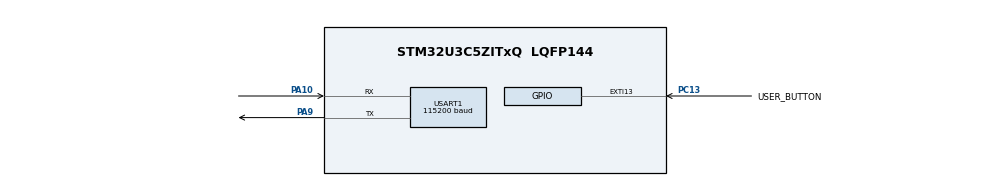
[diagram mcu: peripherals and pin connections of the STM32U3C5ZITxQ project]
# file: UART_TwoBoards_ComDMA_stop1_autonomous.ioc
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CORTEX_M33_NS.userName=CORTEX_M33
GPDMA1.DESTINC_GPDMACH0=DMA_DINC_INCREMENTED
GPDMA1.DESTINC_GPDMACH1=DMA_DINC_FIXED
GPDMA1.DIRECTION_GPDMACH0=DMA_PERIPH_TO_MEMORY
GPDMA1.DIRECTION_GPDMACH1=DMA_MEMORY_TO_PERIPH
GPDMA1.IPHANDLE_GPDMACH0-SIMPLEREQUEST_GPDMACH0=__NULL
GPDMA1.IPHANDLE_GPDMACH1-SIMPLEREQUEST_GPDMACH1=__NULL
GPDMA1.REQUEST_GPDMACH0=GPDMA1_REQUEST_USART1_RX
GPDMA1.REQUEST_GPDMACH1=GPDMA1_REQUEST_USART1_TX
GPDMA1.SRCINC_GPDMACH0=DMA_SINC_FIXED
GPDMA1.SRCINC_GPDMACH1=DMA_SINC_INCREMENTED
GPDMA1.TRANSFERALLOCATEDPORTDEST_GPDMACH0=DMA_DEST_ALLOCATED_PORT1
GPDMA1.TRANSFERALLOCATEDPORTDEST_GPDMACH1=DMA_DEST_ALLOCATED_PORT1
GPDMA1.TRANSFERALLOCATEDPORTSRC_GPDMACH0=DMA_SRC_ALLOCATED_PORT0
GPDMA1.TRANSFERALLOCATEDPORTSRC_GPDMACH1=DMA_SRC_ALLOCATED_PORT0
Mcu.Family=STM32U3
Mcu.Name=STM32U3C5ZITxQ
Mcu.Package=LQFP144
NVIC.EXTI13_IRQn=true\:0\:0\:false\:false\:true\:true\:true\:true
NVIC.GPDMA1_Channel0_IRQn=true\:0\:0\:false\:false\:true\:false\:true\:true
NVIC.GPDMA1_Channel1_IRQn=true\:0\:0\:false\:false\:true\:false\:true\:true
NVIC.PriorityGroup=NVIC_PRIORITYGROUP_4
NVIC.USART1_IRQn=true\:0\:0\:false\:false\:true\:true\:true\:true
PA10.GPIO_PuPd=GPIO_PULLUP
PA10.Mode=Asynchronous
PA10.Signal=USART1_RX
PA9.GPIO_PuPd=GPIO_PULLUP
PA9.Mode=Asynchronous
PA9.Signal=USART1_TX
PC13.GPIO_Label=USER_BUTTON
PC13.GPIO_ModeDefaultEXTI=GPIO_MODE_IT_RISING
PC13.GPIO_PuPd=GPIO_PULLDOWN
PC13.Signal=GPXTI13
ProjectManager.HeapSize=0x200
ProjectManager.StackSize=0x400
ProjectManager.TargetToolchain=EWARM V9.20
RCC.ADCFreq_Value=96000000
RCC.AHBFreq_Value=96000000
RCC.APB1Freq_Value=96000000
RCC.APB1TimFreq_Value=96000000
RCC.APB2Freq_Value=96000000
RCC.APB2TimFreq_Value=96000000
RCC.APB3Freq_Value=96000000
RCC.CortexFreq_Value=12000000
RCC.HCLKFreq_Value=96000000
RCC.HSE_VALUE=16000000
RCC.HSI48_VALUE=48000000
RCC.HSI_VALUE=16000000
RCC.LSE_VALUE=32768
RCC.LSIDIV_VALUE=32000
RCC.MSIKDIV=RCC_MSI_DIV4
RCC.MSIKSource=RCC_MSI_RC1
RCC.MSISDIV=RCC_MSI_DIV1
RCC.MSISSource=RCC_MSI_RC0
RCC.PWR_Regulator_Voltage_Scale=PWR_REGULATOR_VOLTAGE_SCALE1
RCC.SYSCLKFreq_VALUE=96000000
RCC.SYSCLKSource=RCC_SYSCLKSOURCE_MSIS
RCC.USART1CLockSelection=RCC_USART1CLKSOURCE_HSI
RCC.USBFreq_Value=96000000
USART1.BaudRate=115200
USART1.ClockPrescaler=PRESCALER_DIV1
USART1.FIFOMode=FIFOMODE_DISABLE
USART1.Mode=MODE_TX_RX
USART1.OneBitSampling=UART_ONE_BIT_SAMPLE_DISABLE
USART1.OverSampling=UART_OVERSAMPLING_16
USART1.Parity=PARITY_NONE
USART1.RXFIFOThreshold=RXFIFO_THRESHOLD_FULL
USART1.StopBits=STOPBITS_1
USART1.TXFIFOThreshold=TXFIFO_THRESHOLD_EMPTY
USART1.VirtualMode-Asynchronous=VM_ASYNC
USART1.WordLength=WORDLENGTH_8B
VP_GPDMA1_VS_GPDMACH0.Mode=SIMPLEREQUEST_GPDMACH0
VP_GPDMA1_VS_GPDMACH1.Mode=SIMPLEREQUEST_GPDMACH1
VP_ICACHE_VS_ICACHE.Mode=DirectMappedCache
VP_PWR_VS_DBSignals.Mode=DisableDeadBatterySignals
VP_PWR_VS_SECSignals.Mode=Security/Privilege
board=custom

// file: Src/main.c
/* USER CODE BEGIN Header */
/**
  ******************************************************************************
  * @file    UART/UART_TwoBoards_ComDMA/Src/main.c
  * @author  MCD Application Team
  * @brief   This sample code shows how to use UART HAL API to transmit
  *          and receive a data buffer with a communication process based on
  *          DMA transfer.
  *          The communication is done using 2 Boards.
  ******************************************************************************
  * @attention
  *
  * Copyright (c) 2025 STMicroelectronics.
  * All rights reserved.
  *
  * This software is licensed under terms that can be found in the LICENSE file
  * in the root directory of this software component.
  * If no LICENSE file comes with this software, it is provided AS-IS.
  *
  ******************************************************************************
  */
/* USER CODE END Header */
#include "main.h"

/* USER CODE BEGIN PD */
/* Enable TRANSMITTER_BOARD only for board 1. Keep it disabled for the receiver build. */
#define TRANSMITTER_BOARD
/* USER CODE END PD */

UART_HandleTypeDef huart1;
DMA_HandleTypeDef handle_GPDMA1_Channel1;
DMA_HandleTypeDef handle_GPDMA1_Channel0;

/* USER CODE BEGIN PV */
__IO ITStatus UartReady = RESET;
__IO uint32_t UserButtonStatus = 0;  /* set to 1 after User Button interrupt  */

/* Buffer used for transmission */
uint8_t aTxBuffer[] = " ****USART1 two-board DMA transfer with Stop1 wakeup and autonomous echo TX****  ****USART1 two-board DMA transfer with Stop1 wakeup and autonomous echo TX**** ";

/* Buffer used for reception */
uint8_t aRxBuffer[RXBUFFERSIZE];

/* USER CODE END PV */

void SystemClock_Config(void);
static void MX_GPIO_Init(void);
static void MX_GPDMA1_Init(void);
static void MX_ICACHE_Init(void);
static void MX_USART1_UART_Init(void);
/* USER CODE BEGIN PFP */
static uint16_t Buffercmp(uint8_t *pBuffer1, uint8_t *pBuffer2, uint16_t BufferLength);
#ifndef TRANSMITTER_BOARD
static void USART1_AutonomousMode_Config(void);
#endif

/* USER CODE END PFP */

/* USER CODE BEGIN 0 */

#ifndef TRANSMITTER_BOARD
static void USART1_AutonomousMode_Config(void)
{
  UART_AutonomousModeConfTypeDef autonomous_config = {0};

  autonomous_config.AutonomousModeState = UART_AUTONOMOUS_MODE_ENABLE;
  autonomous_config.TriggerSelection = UART_GPDMA1_CH0_TCF_TRG;
  autonomous_config.TriggerPolarity = UART_TRIG_POLARITY_RISING;
  autonomous_config.DataSize = TXBUFFERSIZE;
  autonomous_config.IdleFrame = UART_IDLE_FRAME_DISABLE;

  if (HAL_UARTEx_SetConfigAutonomousMode(&huart1, &autonomous_config) != HAL_OK)
  {
    Error_Handler();
  }
}
#endif

/* USER CODE END 0 */

int main(void)
{

  /* USER CODE BEGIN 1 */
  /* STM32U3xx HAL library initialization:
       - Configure the Flash prefetch
       - Configure the Systick to generate an interrupt each 1 msec
       - Set NVIC Group Priority to 3
       - Low Level Initialization
     */
  /* USER CODE END 1 */

  /* MCU Configuration--------------------------------------------------------*/

  /* Reset of all peripherals, Initializes the Flash interface and the Systick. */
  HAL_Init();

  /* Configure the system clock */
  SystemClock_Config();

  /* Initialize all configured peripherals */
  MX_GPIO_Init();
  MX_GPDMA1_Init();
  MX_ICACHE_Init();
  MX_USART1_UART_Init();
  /* USER CODE BEGIN 2 */

  /* Configure LD1 */
  BSP_LED_Init(LD1);

#ifdef TRANSMITTER_BOARD
  /* Configure User push-button in Interrupt mode */
  BSP_PB_Init(BUTTON_USER, BUTTON_MODE_EXTI);

  /* Wait for User push-button press before starting the Communication.
     In the meantime, LD1 is blinking */
  while (UserButtonStatus == 0)
  {
    /* Toggle LD1*/
    BSP_LED_Toggle(LD1);
    HAL_Delay(100);
  }

  BSP_LED_Off(LD1);
#endif

#ifdef TRANSMITTER_BOARD

  /* The board sends the message and expects to receive it back */
  /* DMA is programmed for reception before starting the transmission, in order to
     be sure DMA Rx is ready when board 2 will start transmitting */

  /*##-2- Program the Reception process #####################################*/
  if (HAL_UART_Receive_DMA(&huart1, (uint8_t *)aRxBuffer, RXBUFFERSIZE) != HAL_OK)
  {
    Error_Handler();
  }

  /*##-3- Start the transmission process #####################################*/
  /* While the UART in reception process, user can transmit data through
     "aTxBuffer" buffer */
  if (HAL_UART_Transmit_DMA(&huart1, (uint8_t *)aTxBuffer, TXBUFFERSIZE) != HAL_OK)
  {
    Error_Handler();
  }

  /*##-4- Wait for the end of the transfer ###################################*/
  while (UartReady != SET)
  {
  }

  /* Reset transmission flag */
  UartReady = RESET;

#else

  UART_WakeUpTypeDef wakeup_config = {0};

  /* The board receives the message, wakes from Stop1, and sends it back */

  /* Keep LD1 on for two seconds so the paired transmitter board can wait
     for the receiver to become ready before it enters Stop1. */
  BSP_LED_On(LD1);
  HAL_Delay(2000);

  /* Disable Debug during Stop mode */
  HAL_DBGMCU_DisableDBGStopMode();

  /* Use RXNE as the USART1 wakeup event while DMA stores the received frame. */
  wakeup_config.WakeUpEvent = UART_WAKEUP_ON_READDATA_NONEMPTY;
  wakeup_config.AddressLength = UART_ADDRESS_DETECT_4B;
  wakeup_config.Address = 0;

  if (HAL_UARTEx_StopModeWakeUpSourceConfig(&huart1, wakeup_config) != HAL_OK)
  {
    Error_Handler();
  }

  if (HAL_UARTEx_EnableStopMode(&huart1) != HAL_OK)
  {
    Error_Handler();
  }

  USART1_AutonomousMode_Config();

  /* Pre-arm the echo path: RX DMA channel 0 completion triggers autonomous TX. */
  if (HAL_UART_Transmit_DMA(&huart1, (uint8_t *)aRxBuffer, TXBUFFERSIZE) != HAL_OK)
  {
    Error_Handler();
  }

  /*##-2- Put UART peripheral in reception process ###########################*/
  if (HAL_UART_Receive_DMA(&huart1, (uint8_t *)aRxBuffer, RXBUFFERSIZE) != HAL_OK)
  {
    Error_Handler();
  }

  /* About to enter Stop1: switch off LD1. */
  BSP_LED_Off(LD1);

  /* Suspend Tick increment to prevent wakeup by SysTick interrupt. */
  HAL_SuspendTick();
  HAL_PWR_EnterSTOPMode(PWR_LOWPOWERMODE_STOP1, PWR_STOPENTRY_WFI);
  HAL_ResumeTick();

  /* Restore the run clock configuration after waking up on USART1 RX activity. */
  SystemClock_Config();

  if (HAL_UARTEx_DisableStopMode(&huart1) != HAL_OK)
  {
    Error_Handler();
  }

  /* Indicate that the core resumed from Stop1. */
  BSP_LED_On(LD1);

  /*##-3- Wait for the end of the transfer ###################################*/
  while (UartReady != SET)
  {
  }

  /* Reset transmission flag */
  UartReady = RESET;

#endif /* TRANSMITTER_BOARD */

  /*##-5- Wait for the end of the transfer ###################################*/
  while (UartReady != SET)
  {
  }

  /* Reset transmission flag */
  UartReady = RESET;

#ifndef TRANSMITTER_BOARD
  if (HAL_UARTEx_ClearConfigAutonomousMode(&huart1) != HAL_OK)
  {
    Error_Handler();
  }
#endif

  /*##-6- Compare the sent and received buffers ##############################*/
  if (Buffercmp((uint8_t *)aTxBuffer, (uint8_t *)aRxBuffer, RXBUFFERSIZE))
  {
    Error_Handler();
  }

  /* Turn on LD1 if test passes then enter infinite loop */
  BSP_LED_On(LD1);

  /* USER CODE END 2 */

  /* Infinite loop */
  while (1)
  {

  }
}

void SystemClock_Config(void)
{
  RCC_OscInitTypeDef RCC_OscInitStruct = {0};
  RCC_ClkInitTypeDef RCC_ClkInitStruct = {0};

  /** Configure the System Power Supply
  */
  if (HAL_PWREx_ConfigSupply(PWR_SMPS_SUPPLY) != HAL_OK)
  {
    Error_Handler();
  }

  /** Enable Epod Booster
  */
  if (HAL_RCCEx_EpodBoosterClkConfig(RCC_EPODBOOSTER_SOURCE_MSIS, RCC_EPODBOOSTER_DIV1) != HAL_OK)
  {
    Error_Handler();
  }
  if (HAL_PWREx_EnableEpodBooster() != HAL_OK)
  {
    Error_Handler();
  }

  /** Configure the main internal regulator output voltage
  */
  if (HAL_PWREx_ControlVoltageScaling(PWR_REGULATOR_VOLTAGE_SCALE1) != HAL_OK)
  {
    Error_Handler();
  }

  /** Set Flash latency before increasing MSIS
  */
  __HAL_FLASH_SET_LATENCY(FLASH_LATENCY_3);

  /** Initializes the CPU, AHB and APB buses clocks
  */
  RCC_OscInitStruct.OscillatorType = RCC_OSCILLATORTYPE_HSI|RCC_OSCILLATORTYPE_MSIS;
  RCC_OscInitStruct.HSIState = RCC_HSI_ON;
  RCC_OscInitStruct.HSICalibrationValue = RCC_HSICALIBRATION_DEFAULT;
  RCC_OscInitStruct.MSISState = RCC_MSI_ON;
  RCC_OscInitStruct.MSISSource = RCC_MSI_RC0;
  RCC_OscInitStruct.MSISDiv = RCC_MSI_DIV1;
  if (HAL_RCC_OscConfig(&RCC_OscInitStruct) != HAL_OK)
  {
    Error_Handler();
  }

  /** Initializes the CPU, AHB and APB buses clocks
  */
  RCC_ClkInitStruct.ClockType = RCC_CLOCKTYPE_HCLK|RCC_CLOCKTYPE_SYSCLK
                              |RCC_CLOCKTYPE_PCLK1|RCC_CLOCKTYPE_PCLK2
                              |RCC_CLOCKTYPE_PCLK3;
  RCC_ClkInitStruct.SYSCLKSource = RCC_SYSCLKSOURCE_MSIS;
  RCC_ClkInitStruct.AHBCLKDivider = RCC_SYSCLK_DIV1;
  RCC_ClkInitStruct.APB1CLKDivider = RCC_HCLK_DIV1;
  RCC_ClkInitStruct.APB2CLKDivider = RCC_HCLK_DIV1;
  RCC_ClkInitStruct.APB3CLKDivider = RCC_HCLK_DIV1;

  if (HAL_RCC_ClockConfig(&RCC_ClkInitStruct, FLASH_LATENCY_3) != HAL_OK)
  {
    Error_Handler();
  }
}

static void MX_GPDMA1_Init(void)
{

  /* Peripheral clock enable */
  __HAL_RCC_GPDMA1_CLK_ENABLE();

  /* GPDMA1 interrupt Init */
    HAL_NVIC_SetPriority(GPDMA1_Channel0_IRQn, 0, 0);
    HAL_NVIC_EnableIRQ(GPDMA1_Channel0_IRQn);
    HAL_NVIC_SetPriority(GPDMA1_Channel1_IRQn, 0, 0);
    HAL_NVIC_EnableIRQ(GPDMA1_Channel1_IRQn);

}

static void MX_ICACHE_Init(void)
{

  /** Enable instruction cache in 1-way (direct mapped cache)
  */
  if (HAL_ICACHE_ConfigAssociativityMode(ICACHE_1WAY) != HAL_OK)
  {
    Error_Handler();
  }
  if (HAL_ICACHE_Enable() != HAL_OK)
  {
    Error_Handler();
  }

}

static void MX_USART1_UART_Init(void)
{

  huart1.Instance = USART1;
  huart1.Init.BaudRate = 115200;
  huart1.Init.WordLength = UART_WORDLENGTH_8B;
  huart1.Init.StopBits = UART_STOPBITS_1;
  huart1.Init.Parity = UART_PARITY_NONE;
  huart1.Init.Mode = UART_MODE_TX_RX;
  huart1.Init.HwFlowCtl = UART_HWCONTROL_NONE;
  huart1.Init.OverSampling = UART_OVERSAMPLING_16;
  huart1.Init.OneBitSampling = UART_ONE_BIT_SAMPLE_DISABLE;
  huart1.Init.ClockPrescaler = UART_PRESCALER_DIV1;
  huart1.AdvancedInit.AdvFeatureInit = UART_ADVFEATURE_NO_INIT;
  if (HAL_UART_Init(&huart1) != HAL_OK)
  {
    Error_Handler();
  }
  if (HAL_UARTEx_SetTxFifoThreshold(&huart1, UART_TXFIFO_THRESHOLD_8_8) != HAL_OK)
  {
    Error_Handler();
  }
  if (HAL_UARTEx_SetRxFifoThreshold(&huart1, UART_RXFIFO_THRESHOLD_8_8) != HAL_OK)
  {
    Error_Handler();
  }
  if (HAL_UARTEx_DisableFifoMode(&huart1) != HAL_OK)
  {
    Error_Handler();
  }

}

static void MX_GPIO_Init(void)
{
  GPIO_InitTypeDef GPIO_InitStruct = {0};

  /* GPIO Ports Clock Enable */
  __HAL_RCC_GPIOC_CLK_ENABLE();
  __HAL_RCC_GPIOA_CLK_ENABLE();

  /*Configure GPIO pin : USER_BUTTON_Pin */
  GPIO_InitStruct.Pin = USER_BUTTON_Pin;
  GPIO_InitStruct.Mode = GPIO_MODE_IT_RISING;
  GPIO_InitStruct.Pull = GPIO_PULLDOWN;
  HAL_GPIO_Init(USER_BUTTON_GPIO_Port, &GPIO_InitStruct);

  /* EXTI interrupt init*/
  HAL_NVIC_SetPriority(USER_BUTTON_EXTI_IRQn, 0, 0);
  HAL_NVIC_EnableIRQ(USER_BUTTON_EXTI_IRQn);

}

/* USER CODE BEGIN 4 */

/**
  * @brief  Tx Transfer completed callback
  * @param  UartHandle: UART handle.
  * @note   This example shows a simple way to report end of DMA Tx transfer, and
  *         you can add your own implementation.
  * @retval None
  */
void HAL_UART_TxCpltCallback(UART_HandleTypeDef *UartHandle)
{
  /* Set transmission flag: transfer complete */
  UartReady = SET;

}

/**
  * @brief  Rx Transfer completed callback
  * @param  UartHandle: UART handle
  * @note   This example shows a simple way to report end of DMA Rx transfer, and
  *         you can add your own implementation.
  * @retval None
  */
void HAL_UART_RxCpltCallback(UART_HandleTypeDef *UartHandle)
{
  /* Set transmission flag: transfer complete */
  UartReady = SET;

}

/**
  * @brief  UART error callbacks
  * @param  UartHandle: UART handle
  * @note   This example shows a simple way to report transfer error, and you can
  *         add your own implementation.
  * @retval None
  */
void HAL_UART_ErrorCallback(UART_HandleTypeDef *UartHandle)
{
  Error_Handler();
}

/**
  * @brief EXTI line detection callbacks
  * @param GPIO_Pin: Specifies the pins connected EXTI line
  * @retval None
  */
  void HAL_GPIO_EXTI_Falling_Callback(uint16_t GPIO_Pin)
{
  if (GPIO_Pin == BUTTON_USER_PIN)
  {
    UserButtonStatus = 1;
  }
}

void HAL_GPIO_EXTI_Rising_Callback(uint16_t GPIO_Pin)
{
    if (GPIO_Pin == BUTTON_USER_PIN)
  {
    UserButtonStatus = 1;
  }
}
/**
  * @brief  Compares two buffers.
  * @param  pBuffer1, pBuffer2: buffers to be compared.
  * @param  BufferLength: buffer's length
  * @retval 0  : pBuffer1 identical to pBuffer2
  *         >0 : pBuffer1 differs from pBuffer2
  */
static uint16_t Buffercmp(uint8_t *pBuffer1, uint8_t *pBuffer2, uint16_t BufferLength)
{
  while (BufferLength--)
  {
    if ((*pBuffer1) != *pBuffer2)
    {
      return BufferLength;
    }
    pBuffer1++;
    pBuffer2++;
  }

  return 0;
}

/* USER CODE END 4 */

void Error_Handler(void)
{
  /* USER CODE BEGIN Error_Handler_Debug */
  /* User can add his own implementation to report the HAL error return state */
  while (1)
  {
    /* Toggle LD1 for error */
    BSP_LED_Toggle(LD1);
    HAL_Delay(500);
  }
  /* USER CODE END Error_Handler_Debug */
}
